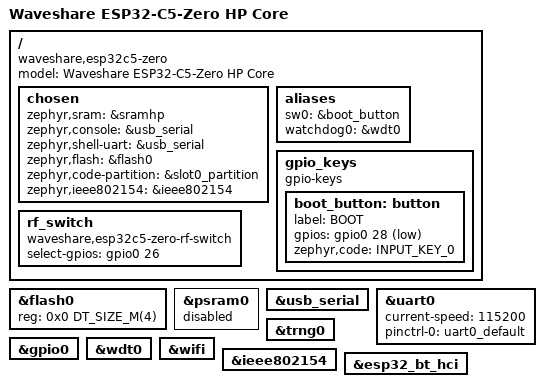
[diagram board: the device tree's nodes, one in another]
/*
 * SPDX-License-Identifier: GPL-3.0-or-later
 *
 * Waveshare ESP32-C5-Zero: ESP32-C5HF4 (4 MB flash in package, no PSRAM),
 * 48 MHz crystal, USB-C on the native USB-Serial-JTAG, chip antenna and
 * U.FL behind an RF switch.
 */

/dts-v1/;

#include <espressif/esp32c5/esp32c5.dtsi>
#include "waveshare_esp32c5_zero_hpcore-pinctrl.dtsi"
#include <zephyr/dt-bindings/input/input-event-codes.h>
#include "waveshare_esp32c5_zero-partitions_4M.dtsi"

/ {
	model = "Waveshare ESP32-C5-Zero HP Core";
	compatible = "waveshare,esp32c5-zero", "espressif,esp32c5";

	chosen {
		zephyr,sram = &sramhp;
		zephyr,console = &usb_serial;
		zephyr,shell-uart = &usb_serial;
		zephyr,flash = &flash0;
		zephyr,code-partition = &slot0_partition;
		zephyr,ieee802154 = &ieee802154;
	};

	aliases {
		sw0 = &boot_button;
		watchdog0 = &wdt0;
	};

	gpio_keys {
		compatible = "gpio-keys";

		boot_button: button {
			label = "BOOT";
			gpios = <&gpio0 28 (GPIO_PULL_UP | GPIO_ACTIVE_LOW)>;
			zephyr,code = <INPUT_KEY_0>;
		};
	};

	/* CONFIG_WAVESHARE_ESP32C5_ZERO_EXT_ANTENNA drives it (board.c). */
	rf_switch: rf_switch {
		compatible = "waveshare,esp32c5-zero-rf-switch";
		select-gpios = <&gpio0 26 GPIO_ACTIVE_HIGH>;
	};
};

&flash0 {
	reg = <0x0 DT_SIZE_M(4)>;
	ranges = <0x0 0x0 DT_SIZE_M(4)>;
};

/* No PSRAM in the ESP32-C5HF4. */
&psram0 {
	status = "disabled";
};

&usb_serial {
	status = "okay";
};

&uart0 {
	status = "okay";
	current-speed = <115200>;
	pinctrl-0 = <&uart0_default>;
	pinctrl-names = "default";
};

&trng0 {
	status = "okay";
};

&gpio0 {
	status = "okay";
};

&wdt0 {
	status = "okay";
};

&wifi {
	status = "okay";
};

&ieee802154 {
	status = "okay";
};

&esp32_bt_hci {
	status = "okay";
};
